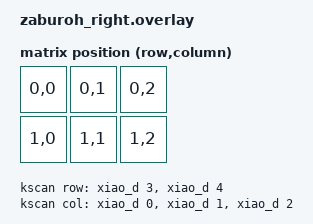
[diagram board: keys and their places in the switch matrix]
// This file was generated from a template. Edit it to match your keyboard.
// See https://zmk.dev/docs/development/hardware-integration/new-shield for more
// instructions.

#include <dt-bindings/zmk/matrix_transform.h>

#include "zaburoh_right-layouts.dtsi"

/ {
    chosen {
        zmk,physical-layout = &default_layout;
    };

    kscan: kscan {
        compatible = "zmk,kscan-gpio-matrix";

        diode-direction = "col2row";
        wakeup-source;

        col-gpios
            = <&xiao_d 0 GPIO_ACTIVE_HIGH>
            , <&xiao_d 1 GPIO_ACTIVE_HIGH>
            , <&xiao_d 2 GPIO_ACTIVE_HIGH>
            ;

        row-gpios
            = <&xiao_d 3 (GPIO_ACTIVE_HIGH | GPIO_PULL_DOWN)>
            , <&xiao_d 4 (GPIO_ACTIVE_HIGH | GPIO_PULL_DOWN)>
            ;
    };

    default_transform: default_transform {
        compatible = "zmk,matrix-transform";
        col-offset = <4>;
        columns = <3>;
        rows = <2>;

        map = <
            RC(0, 0) RC(0, 1) RC(0, 2)
            RC(1, 0) RC(1, 1) RC(1, 2)
        >;
    };
};
